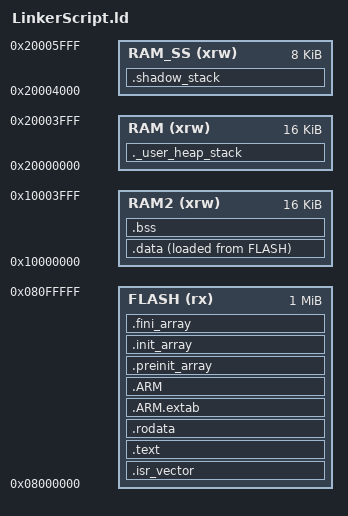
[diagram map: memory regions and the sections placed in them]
/*
*****************************************************************************
**

**  File        : stm32_flash.ld
**
**  Abstract    : Linker script for STM32L476VG Device with
**                1024KByte FLASH, 96KByte RAM
**
**                Set heap size, stack size and stack location according
**                to application requirements.
**
**                Set memory bank area and size if external memory is used.
**
**  Target      : STMicroelectronics STM32
**
**  Environment : SYSTEM WORKBENCH for STM32
**
**  Distribution: The file is distributed as is, without any warranty
**                of any kind.
**
**  (c)Copyright STMicroelectronics.
**
*****************************************************************************
*/

/* Entry Point */
ENTRY(Reset_Handler)

/* Highest address of the user mode stack */
_estack = 0x20003FFC; /* End of RAM */

/* Highest address of the shadow stack */
_esstack = 0x20006000; /* End of RAM_SS */

/* Generate a link error if heap and stack don't fit into RAM */
_Min_Heap_Size  = 0x200; /* required amount of heap  */
_Min_Stack_Size = 0x400; /* required amount of stack */

/* Specify the memory areas */
MEMORY
{
FLASH (rx)     : ORIGIN = 0x8000000,  LENGTH = 1024K
RAM2 (xrw)     : ORIGIN = 0x10000000, LENGTH = 16K /* heap top: 0x1000,4000 */
RAM (xrw)      : ORIGIN = 0x20000000, LENGTH = 16K /* stack top: 0x2000,4000 */
RAM_SS(xrw)    : ORIGIN = 0x20004000, LENGTH = 8K /* shadow stack top: 0x2000,6000 */
}

/* Define output sections */
SECTIONS
{
  /* The startup code goes first into FLASH */
  .isr_vector :
  {
    . = ALIGN(8);
    KEEP(*(.isr_vector)) /* Startup code */
    . = ALIGN(8);
  } >FLASH

  /* The program code and other data goes into FLASH */
  .text :
  {
    . = ALIGN(8);
    *(.text)           /* .text sections (code) */
    *(.text*)          /* .text* sections (code) */
    *(.glue_7)         /* glue arm to thumb code */
    *(.glue_7t)        /* glue thumb to arm code */
    *(.eh_frame)

    KEEP (*(.init))
    KEEP (*(.fini))

    . = ALIGN(8);
    _etext = .;        /* define a global symbols at end of code */
  } >FLASH

  /* Constant data goes into FLASH */
  .rodata :
  {
    . = ALIGN(8);
    *(.rodata)         /* .rodata sections (constants, strings, etc.) */
    *(.rodata*)        /* .rodata* sections (constants, strings, etc.) */
    . = ALIGN(8);
  } >FLASH

  .ARM.extab   :
  {
    . = ALIGN(8);
	*(.ARM.extab* .gnu.linkonce.armextab.*)
    . = ALIGN(8);
  } >FLASH

  .ARM :
  {
    . = ALIGN(8);
    __exidx_start = .;
    *(.ARM.exidx*)
    __exidx_end = .;
    . = ALIGN(8);
  } >FLASH

  .preinit_array     :
  {
    . = ALIGN(8);
    PROVIDE_HIDDEN (__preinit_array_start = .);
    KEEP (*(.preinit_array*))
    PROVIDE_HIDDEN (__preinit_array_end = .);
    . = ALIGN(8);
  } >FLASH

  .init_array :
  {
    . = ALIGN(8);
    PROVIDE_HIDDEN (__init_array_start = .);
    KEEP (*(SORT(.init_array.*)))
    KEEP (*(.init_array*))
    PROVIDE_HIDDEN (__init_array_end = .);
    . = ALIGN(8);
  } >FLASH

  .fini_array :
  {
    . = ALIGN(8);
    PROVIDE_HIDDEN (__fini_array_start = .);
    KEEP (*(SORT(.fini_array.*)))
    KEEP (*(.fini_array*))
    PROVIDE_HIDDEN (__fini_array_end = .);
    . = ALIGN(8);
  } >FLASH

  /* used by the startup to initialize data */
  _sidata = LOADADDR(.data);

  /* Initialized data sections goes into RAM, load LMA copy after code */
  .data :
  {
    . = ALIGN(8);
    _sdata = .;        /* create a global symbol at data start */
    *(.data)           /* .data sections */
    *(.data*)          /* .data* sections */

    . = ALIGN(8);
    _edata = .;        /* define a global symbol at data end */
  } >RAM2 AT> FLASH

  /* Uninitialized data section */
  . = ALIGN(4);
  .bss :
  {
    /* This is used by the startup in order to initialize the .bss secion */
    _sbss = .;         /* define a global symbol at bss start */
    __bss_start__ = _sbss;
    *(.bss)
    *(.bss*)
    *(COMMON)

    . = ALIGN(4);
    _ebss = .;         /* define a global symbol at bss end */
    __bss_end__ = _ebss;
  } >RAM2

  /* User_heap_stack section, used to check that there is enough RAM left */
  ._user_heap_stack :
  {
    . = ALIGN(8);
    PROVIDE ( end = . );
    PROVIDE ( _end = . );
    . = . + _Min_Heap_Size;
    . = . + _Min_Stack_Size;
    . = ALIGN(8);
  } >RAM

  /* the faked stack data, for testing only */
  .shadow_stack :
  {
    . = ALIGN(0x20);
    _shadow_stack_start = .;
    *(.shadow_stack)
    . = ALIGN(0x20);
  } >RAM_SS

  /* Remove information from the standard libraries */
  /DISCARD/ :
  {
    libc.a ( * )
    libm.a ( * )
    libgcc.a ( * )
  }

  .ARM.attributes 0 : { *(.ARM.attributes) }
}

_FLASH_segment_start = ORIGIN(FLASH);
_FLASH_segment_end = _FLASH_segment_start + LENGTH(FLASH);

_RAM_start = ORIGIN(RAM);
_RAM_end = _RAM_start + LENGTH(RAM);

_RAM2_start = ORIGIN(RAM2);
_RAM2_end = _RAM2_start + LENGTH(RAM2);

_shadow_stack_start = ORIGIN(RAM_SS);
_shadow_stack_end = _shadow_stack_start + LENGTH(RAM_SS);
